# CEC1702 register map
Vendor: Microchip
Registers are 32-bit, read-write, reset 0x0 unless marked. A register's access mark holds for its fields unless they carry their own. Addresses are absolute, and some are shared; only a register's first bit layout is shown; [hi:lo] are bit positions.

## PWM5
0x40005850 CNT_ON
0x40005854 CNT_OFF
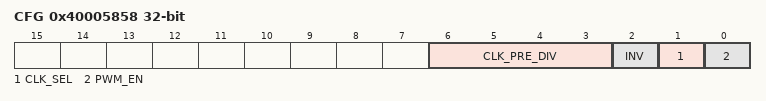
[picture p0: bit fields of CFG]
0x40005858 CFG
  [6:3] CLK_PRE_DIV — The Clock source for the 16-bit down counter (see PWMx Counter ON Time Register and PWMx Counter OFF Time Register) is determined by bit D1 of this register. The Clock source is then divided by the value of Pre-Divider+1 and the resulting signal determines the rate at which the down counter will be decremented. For example, a Pre-Divider value of 1 divides the input clock by 2 and a value of 2 divides the input clock by 3. A Pre-Divider of 0 will disable the Pre-Divider option.
  [2] INV — 1= PWM_OUTPUT ON State is active low; 0=PWM_OUTPUT ON State is active high.
  [1] CLK_SEL — This bit determines the clock source used by the PWM duty cycle and frequency control logic. 1=CLOCK_LOW. 0=CLOCK_HIGH
  [0] PWM_EN — When the PWM_EN is set to 0 the internal counters are reset and the internal state machine is set to the OFF state. In addition, the PWM_OUTPUT signal is set to the inactive state as determined by the Invert bit. The PWMx Counter ON Time Register and PWMx Counter OFF Time Register are not affected by the PWM_ENABLE bit and may be read and written while the PWM enable bit is 0. 1=Enabled (default); 0=Disabled (gates clocks to save power).

## PWM10
0x400058A0 CNT_ON
0x400058A4 CNT_OFF
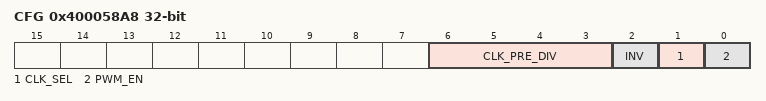
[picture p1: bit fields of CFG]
0x400058A8 CFG
  [6:3] CLK_PRE_DIV — The Clock source for the 16-bit down counter (see PWMx Counter ON Time Register and PWMx Counter OFF Time Register) is determined by bit D1 of this register. The Clock source is then divided by the value of Pre-Divider+1 and the resulting signal determines the rate at which the down counter will be decremented. For example, a Pre-Divider value of 1 divides the input clock by 2 and a value of 2 divides the input clock by 3. A Pre-Divider of 0 will disable the Pre-Divider option.
  [2] INV — 1= PWM_OUTPUT ON State is active low; 0=PWM_OUTPUT ON State is active high.
  [1] CLK_SEL — This bit determines the clock source used by the PWM duty cycle and frequency control logic. 1=CLOCK_LOW. 0=CLOCK_HIGH
  [0] PWM_EN — When the PWM_EN is set to 0 the internal counters are reset and the internal state machine is set to the OFF state. In addition, the PWM_OUTPUT signal is set to the inactive state as determined by the Invert bit. The PWMx Counter ON Time Register and PWMx Counter OFF Time Register are not affected by the PWM_ENABLE bit and may be read and written while the PWM enable bit is 0. 1=Enabled (default); 0=Disabled (gates clocks to save power).

## TACH0
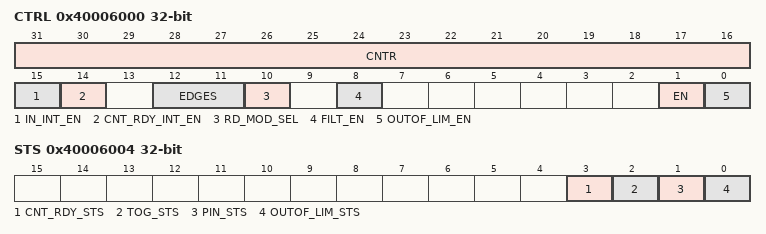
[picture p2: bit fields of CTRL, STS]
0x40006000 CTRL
  [31:16] CNTR — This 16-bit field contains the latched value of the internal Tach pulse counter, which may be configured by the. Tach Reading Mode Select field to operate as a free-running counter or to be gated by the Tach input signal.
  [15] IN_INT_EN — IN_INT_EN 1=Enable Tach Input toggle interrupt from Tach block, 0=Disable Tach Input toggle interrupt from Tach block
  [14] CNT_RDY_INT_EN — CNT_RDY_INT_EN 1=Enable Count Ready interrupt from Tach block, 0=Disable Count Ready interrupt from Tach block
  [12:11] EDGES — EDGES A Tach signal is a square wave with a 50% duty cycle. Typically, two Tach periods represents one revolution of the fan. A Tach period consists of three Tach edges. This programmed value represents the number of Tach edges that will be used to determine the interval for which the number of 100kHz_Clk pulses will be counted. 11b=9 Tach edges (4 Tach periods). 10b=5 Tach edges (2 Tach periods). 01b=3 Tach edges (1 Tach period). 00b=2 Tach edges (1/2 Tach period)
  [10] RD_MOD_SEL — RD_MOD_SEL. 1=Counter is incremented on the rising edge of the 100kHz_Clk input. The counter is latched into the TACHX_COUNTER field and reset when the programmed number of edges is detected. 0=Counter is incremented when Tach Input transitions from low-tohigh state (default)
  [8] FILT_EN — FILT_EN This filter is used to remove high frequency glitches from Tach Input. When this filter is enabled, Tach input pulses less than two 100kHz_- Clk periods wide get filtered. 1= Filter enabled. 0= Filter disabled (default). It is recommended that the Tach input filter always be enabled.
  [1] EN — EN 1= TACH Monitoring enabled, clocks enabled. 0= TACH Idle, clocks gated
  [0] OUTOF_LIM_EN — OUTOF_LIM_EN This bit is used to enable the TACH_OUT_OF_LIMIT_STATUS bit in the TACHx Status Register to generate an interrupt event. 1=Enable interrupt output from Tach block. 0=Disable interrupt output from Tach block (default)
0x40006004 STS
  [3] CNT_RDY_STS — CNT_RDY_STS 1=Reading ready, 0=Reading not ready
  [2] TOG_STS — TOG_STS 1=Tach Input changed state (this bit is set on a low-to-high or high-tolow transition), 0=Tach stable (R/WC)
  [1] PIN_STS — PIN_STS 1= Tach Input is high, 0= Tach Input is low
  [0] OUTOF_LIM_STS — OUTOF_LIM_STS 1=Tach is outside of limits, 0=Tach is within limits (R/WC)
0x40006008 LIM_HI reset 0xFFFF
  [15:0] T_HIGH — This value is compared with the value in the TACHX_COUNTER field. If the value in the counter is greater than the value programmed in this register, the TACH_OUT_OF_LIMIT_STATUS bit will be set. The TACH_OUT_OF_LIMIT_STATUS status event may be enabled to generate an interrupt to the embedded controller via the TACH_OUT_OF_LIMIT_ENABLE bit in the TACHx Control Register.
0x4000600C LIM_LO
  [15:0] T_LOW — This value is compared with the value in the TACHX_COUNTER field of the TACHx Control Register. If the value in the counter is less than the value programmed in this register, the TACH_OUT_OF_LIMIT_STATUS bit will be set. The TACH_OUT_OF_LIMIT_STATUS status event may be enabled to generate an interrupt to the embedded controller via the TACH_OUT_OF_LIMIT_ENABLE bit in the TACHx. Control Register To disable the TACH_OUT_OF_LIMIT_STATUS low event, program 0000h into this register.
